AUTOSAR XML (schema 00046)
package /MICROSAR/SecOC_swc/DataTypes
  impl type SecOC_VerificationResultType: compu {0=SECOC_VERIFICATIONSUCCESS, 1=SECOC_VERIFICATIONFAILURE, 2=SECOC_FRESHNESSFAILURE, 3=SECOC_AUTHENTICATIONBUILDFAILURE, 4=SECOC_NO_VERIFICATION, 5=SECOC_VERIFICATIONFAILURE_OVERWRITTEN}, range raw 0..5, implementation-data-type=uint8
  impl type SecOC_VerificationStatusType: category=STRUCTURE
    element freshnessValueID: range raw 0..65535, implementation-data-type=uint16
    element verificationStatus: implementation-data-type=SecOC_VerificationResultType
    element secOCDataId: range raw 0..65535, implementation-data-type=uint16
package /MICROSAR/SecOC_swc/Interfaces
  sender receiver interface SecOC_VerificationStatusService: is-service=true, service-kind=VENDOR-SPECIFIC
    data verificationStatus: type=SecOC_VerificationStatusType
  client server interface SecOC_VerifyStatusConfiguration: is-service=true, service-kind=VENDOR-SPECIFIC
    operation VerifyStatusOverride: possible-error=[E_OK, E_NOT_OK]
      arg freshnessValueID: type=uint16, direction=IN  # ID of the Freshness Value which when used to authenticate data, results in SecOC_VerifyStatus equal to OverrideStatus independent of the actual authentication status.
      arg overrideStatus: type=uint8, direction=IN  # Defines whether verification is executed and whether the I-PDU is passed on, and for how long the override is active.
      arg numberOfMessagesToOverride: type=uint8, direction=IN  # Number of sequential VerifyStatus to override when using a specific counter for authentication verification.
    error E_OK: error-code=0
    error E_NOT_OK: error-code=1
package /MICROSAR/SecOC_swc/ComponentTypes
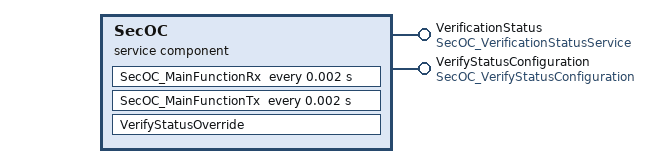
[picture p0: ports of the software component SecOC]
  service sw component type SecOC: category=SERVICE_COMPONENT
    provide port VerificationStatus: nonqueued-sender-com-spec{data-element=verificationStatus, init-value=fields=[0, SECOC_VERIFICATIONFAILURE, 0]}, provided-interface=SecOC_VerificationStatusService
    provide port VerifyStatusConfiguration: provided-interface=SecOC_VerifyStatusConfiguration
    behavior SecOCInternalBehavior: handle-termination-and-restart=NO-SUPPORT, included-data-type-set=data-type=[SecOC_VerificationResultType, SecOC_VerificationStatusType]
      timing event Timer_SecOC_MainFunctionRx: start-on-event=SecOC_MainFunctionRx, period=0.002
      timing event Timer_SecOC_MainFunctionTx: start-on-event=SecOC_MainFunctionTx, period=0.002
      operation invoked event OpEventVerifyStatusOverride_VerifyStatusOverride_VerifyStatusConfiguration: start-on-event=VerifyStatusOverride, operation=VerifyStatusConfiguration.VerifyStatusOverride
      port-api-options:
        enable-take-address=true, indirect-api=false, port=VerificationStatus
        enable-take-address=true, indirect-api=false, port=VerifyStatusConfiguration
      runnable SecOC_MainFunctionRx: can-be-invoked-concurrently=true
        data-send-points:
          access DataSendPointSecOC_MainFunctionRx_VerificationStatus_verificationStatus: accessed-variable=VerificationStatus.verificationStatus
      runnable SecOC_MainFunctionTx: can-be-invoked-concurrently=true
      runnable VerifyStatusOverride: can-be-invoked-concurrently=true, symbol=SecOC_VerifyStatusOverride
  swc implementation SecOCImplementation: programming-language=C, behavior=SecOCInternalBehavior
